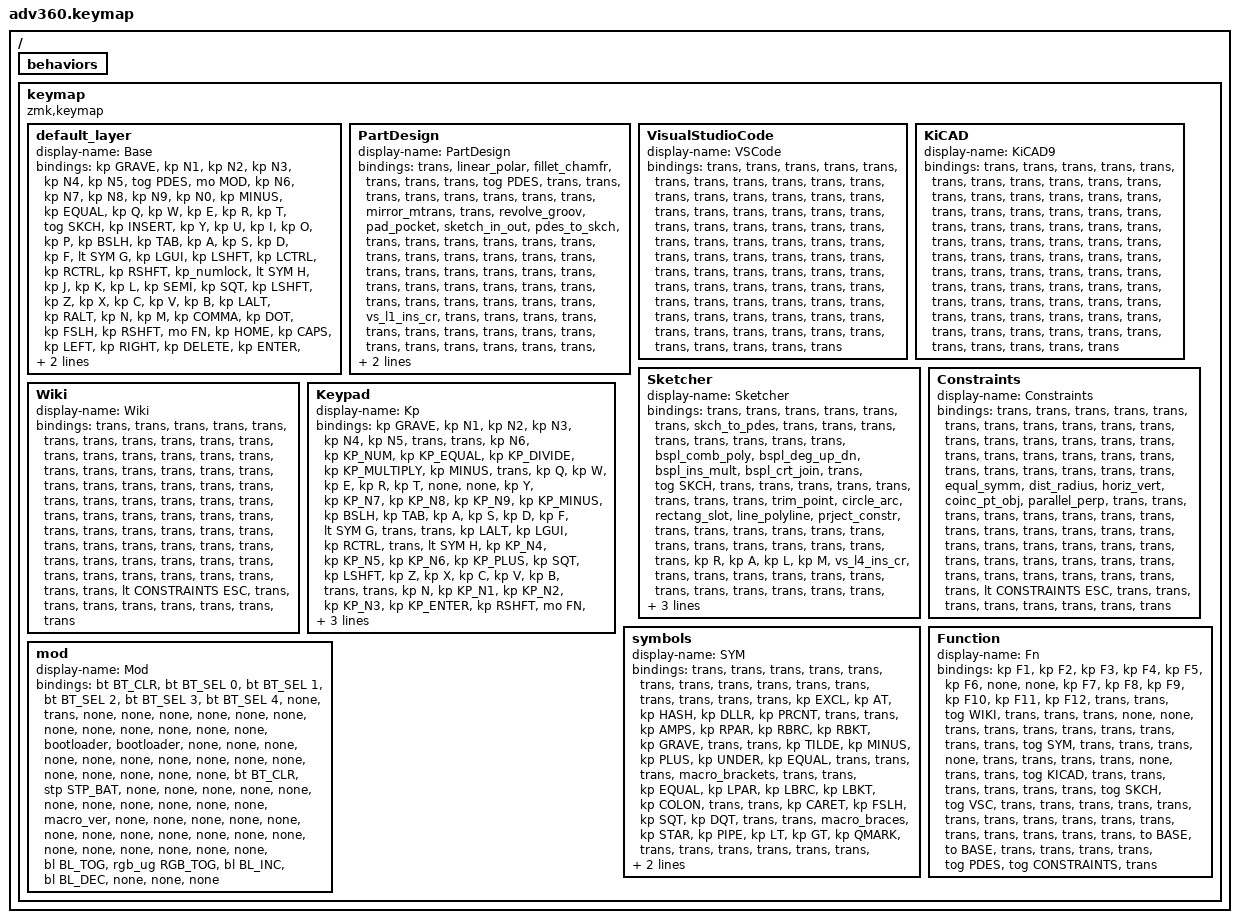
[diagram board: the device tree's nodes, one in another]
// ╔══════════════════════════════════════════════════════════════════════════╗
// ║  VISUAL HELPER TABLES: Each layer has an ASCII art comment block         ║
// ║  above its bindings that mirrors the physical key layout.                ║
// ║                                                                          ║
// ║  RULE: When editing ANY layer's bindings, the corresponding ASCII        ║
// ║  table comment MUST be updated to reflect the change. NEVER strip        ║
// ║  these comments. They are the human-readable source of truth.            ║
// ╚══════════════════════════════════════════════════════════════════════════╝

#include <behaviors.dtsi>
#include <dt-bindings/zmk/keys.h>
#include <dt-bindings/zmk/bt.h>
#include <dt-bindings/zmk/rgb.h>
#include <dt-bindings/zmk/stp.h>
#include <dt-bindings/zmk/backlight.h>
#include <dt-bindings/zmk/pointing.h>

#define BASE 0
#define PDES 1
#define VSC 2
#define KICAD 3
#define SKCH 4
#define CONSTRAINTS 5
#define WIKI 6
#define KP 7
#define SYM 8
#define FN 9
#define MOD 10

/ {
    behaviors {
      #include "version.dtsi"
      #include "macros.dtsi"
      #include "freecad.dtsi"
    };

  keymap {
    compatible = "zmk,keymap";

    default_layer {
      display-name = "Base";
      // ╔══════════════╦══════════════╦══════════════╦══════════════╦══════════════╦══════════════╦══════════════╗                                                                          ╔══════════════╦══════════════╦══════════════╦══════════════╦══════════════╦══════════════╦══════════════╗
      // ║  &kp GRAVE   ║    &kp N1    ║    &kp N2    ║    &kp N3    ║    &kp N4    ║    &kp N5    ║  &tog PDES   ║                                                                          ║   &mo MOD    ║    &kp N6    ║    &kp N7    ║    &kp N8    ║    &kp N9    ║    &kp N0    ║  &kp MINUS   ║
      // ╠══════════════╬══════════════╬══════════════╬══════════════╬══════════════╬══════════════╬══════════════╣                                                                          ╠══════════════╬══════════════╬══════════════╬══════════════╬══════════════╬══════════════╬══════════════╣
      // ║  &kp EQUAL   ║    &kp Q     ║    &kp W     ║    &kp E     ║    &kp R     ║    &kp T     ║  &tog SKCH   ║                                                                          ║  &kp INSERT  ║    &kp Y     ║    &kp U     ║    &kp I     ║    &kp O     ║    &kp P     ║   &kp BSLH   ║
      // ╠══════════════╬══════════════╬══════════════╬══════════════╬══════════════╬══════════════╬══════════════╣   ╔══════════════╦══════════════╗╔═══════════════╦══════════════╗        ╠══════════════╬══════════════╬══════════════╬══════════════╬══════════════╬══════════════╬══════════════╣
      // ║   &kp TAB    ║    &kp A     ║    &kp S     ║    &kp D     ║    &kp F     ║  &lt SYM G   ║   &kp LGUI   ║   ║  &kp LSHFT   ║  &kp LCTRL   ║║   &kp RCTRL   ║  &kp RSHFT   ║        ║ &kp_numlock  ║  &lt SYM H   ║    &kp J     ║    &kp K     ║    &kp L     ║   &kp SEMI   ║   &kp SQT    ║
      // ║              ║              ║              ║              ║              ║              ║              ║   ║              ║              ║║               ║              ║        ║              ║              ║              ║              ║              ║              ║              ║
      // ╠══════════════╬══════════════╬══════════════╬══════════════╬══════════════╬══════════════╬══════════════╝   ╚══════════════╬══════════════╣╠═══════════════╬══════════════╝        ╚══════════════╬══════════════╬══════════════╬══════════════╬══════════════╬══════════════╬══════════════╣
      // ║  &kp LSHFT   ║    &kp Z     ║    &kp X     ║    &kp C     ║    &kp V     ║    &kp B     ║                                 ║   &kp LALT   ║║   &kp RALT    ║                                      ║    &kp N     ║    &kp M     ║  &kp COMMA   ║   &kp DOT    ║   &kp FSLH   ║  &kp RSHFT   ║
      // ╠══════════════╬══════════════╬══════════════╬══════════════╬══════════════╬══════════════╝ ╔════════════════╦══════════════╬══════════════╣╠═══════════════╬══════════════╦═══════════╗           ╚══════════════╬══════════════╬══════════════╬══════════════╬══════════════╬══════════════╣
      // ║    &mo FN    ║   &kp HOME   ║   &kp CAPS   ║   &kp LEFT   ║  &kp RIGHT   ║                ║   &kp DELETE   ║  &kp ENTER   ║   &kp ESC    ║║    &kp ESC    ║  &kp SPACE   ║ &kp BSPC  ║                          ║    &kp UP    ║   &kp DOWN   ║   &kp LBKT   ║   &kp RBKT   ║    &mo FN    ║
      // ╚══════════════╩══════════════╩══════════════╩══════════════╩══════════════╝                ╚════════════════╩══════════════╩══════════════╝╚═══════════════╩══════════════╩═══════════╝                          ╚══════════════╩══════════════╩══════════════╩══════════════╩══════════════╝
            bindings = <
        &kp GRAVE &kp N1    &kp N2   &kp N3   &kp N4     &kp N5 &tog PDES                                                      &mo MOD    &kp N6 &kp N7 &kp N8    &kp N9   &kp N0   &kp MINUS
        &kp EQUAL &kp Q     &kp W    &kp E    &kp R      &kp T  &tog SKCH                                                      &kp INSERT &kp Y  &kp U  &kp I     &kp O    &kp P    &kp BSLH
        &kp TAB   &kp A     &kp S    &kp D    &kp F  &lt SYM G  &kp LGUI        &kp LSHFT    &kp LCTRL  &kp RCTRL &kp RSHFT   &kp_numlock &lt SYM H &kp J  &kp K     &kp L    &kp SEMI &kp SQT
        &kp LSHFT &kp Z     &kp X    &kp C    &kp V      &kp B                               &kp LALT  &kp RALT                        &kp N  &kp M  &kp COMMA &kp DOT  &kp FSLH &kp RSHFT
        &mo FN    &kp HOME  &kp CAPS &kp LEFT &kp RIGHT                &kp DELETE  &kp ENTER &kp ESC    &kp ESC   &kp SPACE  &kp BSPC         &kp UP &kp DOWN  &kp LBKT &kp RBKT &mo FN
      >;
    };

    PartDesign {
      display-name = "PartDesign";
      // ╔══════════════╦══════════════╦══════════════╦══════════════╦══════════════╦══════════════╦══════════════╗                                                                          ╔══════════════╦══════════════╦══════════════╦══════════════╦══════════════╦══════════════╦══════════════╗
      // ║    &trans    ║&linear_polar ║&fillet_chamfr║    &trans    ║    &trans    ║    &trans    ║  &tog PDES   ║                                                                          ║    &trans    ║    &trans    ║    &trans    ║    &trans    ║    &trans    ║  &vs_l1_ins_cr  ║    &trans    ║
      // ╠══════════════╬══════════════╬══════════════╬══════════════╬══════════════╬══════════════╬══════════════╣                                                                          ╠══════════════╬══════════════╬══════════════╬══════════════╬══════════════╬══════════════╬══════════════╣
      // ║    &trans    ║&mirror_mtrans║    &trans    ║&revolve_groov║ &pad_pocket  ║&sketch_in_out║&pdes_to_skch ║                                                                          ║    &trans    ║    &trans    ║    &trans    ║    &trans    ║    &trans    ║    &trans    ║    &trans    ║
      // ╠══════════════╬══════════════╬══════════════╬══════════════╬══════════════╬══════════════╬══════════════╣   ╔══════════════╦══════════════╗╔═══════════════╦══════════════╗        ╠══════════════╬══════════════╬══════════════╬══════════════╬══════════════╬══════════════╬══════════════╣
      // ║    &trans    ║    &trans    ║    &trans    ║    &trans    ║    &trans    ║    &trans    ║    &trans    ║   ║    &trans    ║    &trans    ║║    &trans     ║    &trans    ║        ║    &trans    ║    &trans    ║    &trans    ║    &trans    ║    &trans    ║    &trans    ║    &trans    ║
      // ║              ║              ║              ║              ║              ║              ║              ║   ║              ║              ║║               ║              ║        ║              ║              ║              ║              ║              ║              ║              ║
      // ╠══════════════╬══════════════╬══════════════╬══════════════╬══════════════╬══════════════╬══════════════╝   ╚══════════════╬══════════════╣╠═══════════════╬══════════════╝        ╚══════════════╬══════════════╬══════════════╬══════════════╬══════════════╬══════════════╬══════════════╣
      // ║    &trans    ║    &trans    ║    &trans    ║    &trans    ║    &trans    ║    &trans    ║                                 ║    &trans    ║║    &trans     ║                                      ║    &trans    ║    &trans    ║    &trans    ║    &trans    ║    &trans    ║    &trans    ║
      // ╠══════════════╬══════════════╬══════════════╬══════════════╬══════════════╬══════════════╝ ╔════════════════╦══════════════╬══════════════╣╠═══════════════╬══════════════╦═══════════╗           ╚══════════════╬══════════════╬══════════════╬══════════════╬══════════════╬══════════════╣
      // ║    &trans    ║    &trans    ║    &trans    ║    &trans    ║    &trans    ║                ║     &trans     ║    &trans    ║    &trans    ║║    &trans     ║    &trans    ║  &trans   ║                          ║    &trans    ║    &trans    ║    &trans    ║    &trans    ║    &trans    ║
      // ╚══════════════╩══════════════╩══════════════╩══════════════╩══════════════╝                ╚════════════════╩══════════════╩══════════════╝╚═══════════════╩══════════════╩═══════════╝                          ╚══════════════╩══════════════╩══════════════╩══════════════╩══════════════╝
            bindings = <
        &trans &linear_polar &fillet_chamfr &trans &trans &trans &tog PDES                                                    &trans &trans &trans &trans &trans &trans &trans
        &trans &mirror_mtrans &trans &revolve_groov &pad_pocket &sketch_in_out &pdes_to_skch                                  &trans &trans &trans &trans &trans &trans &trans
        &trans &trans &trans &trans &trans &trans &trans       &trans &trans    &trans &trans &trans &trans &trans &trans &trans &trans &trans
        &trans &trans &trans &trans &trans &vs_l1_ins_cr                 &trans &trans                     &trans &trans &trans &trans &trans &trans
        &trans &trans &trans &trans &trans        &trans &trans &trans       &trans &trans &trans        &trans &trans &trans &trans &trans
      >;
    };

    VisualStudioCode {
      display-name = "VSCode";
      // ╔══════════════╦══════════════╦══════════════╦══════════════╦══════════════╦══════════════╦══════════════╗                                                                          ╔══════════════╦══════════════╦══════════════╦══════════════╦══════════════╦══════════════╦══════════════╗
      // ║    &trans    ║    &trans    ║    &trans    ║    &trans    ║    &trans    ║    &trans    ║    &trans    ║                                                                          ║    &trans    ║    &trans    ║    &trans    ║    &trans    ║    &trans    ║    &trans    ║    &trans    ║
      // ╠══════════════╬══════════════╬══════════════╬══════════════╬══════════════╬══════════════╬══════════════╣                                                                          ╠══════════════╬══════════════╬══════════════╬══════════════╬══════════════╬══════════════╬══════════════╣
      // ║    &trans    ║    &trans    ║    &trans    ║    &trans    ║    &trans    ║    &trans    ║    &trans    ║                                                                          ║    &trans    ║    &trans    ║    &trans    ║    &trans    ║    &trans    ║    &trans    ║    &trans    ║
      // ╠══════════════╬══════════════╬══════════════╬══════════════╬══════════════╬══════════════╬══════════════╣   ╔══════════════╦══════════════╗╔═══════════════╦══════════════╗        ╠══════════════╬══════════════╬══════════════╬══════════════╬══════════════╬══════════════╬══════════════╣
      // ║    &trans    ║    &trans    ║    &trans    ║    &trans    ║    &trans    ║    &trans    ║    &trans    ║   ║    &trans    ║    &trans    ║║    &trans     ║    &trans    ║        ║    &trans    ║    &trans    ║    &trans    ║    &trans    ║    &trans    ║    &trans    ║    &trans    ║
      // ║              ║              ║              ║              ║              ║              ║              ║   ║              ║              ║║               ║              ║        ║              ║              ║              ║              ║              ║              ║              ║
      // ╠══════════════╬══════════════╬══════════════╬══════════════╬══════════════╬══════════════╬══════════════╝   ╚══════════════╬══════════════╣╠═══════════════╬══════════════╝        ╚══════════════╬══════════════╬══════════════╬══════════════╬══════════════╬══════════════╬══════════════╣
      // ║    &trans    ║    &trans    ║    &trans    ║    &trans    ║    &trans    ║    &trans    ║                                 ║    &trans    ║║    &trans     ║                                      ║    &trans    ║    &trans    ║    &trans    ║    &trans    ║    &trans    ║    &trans    ║
      // ╠══════════════╬══════════════╬══════════════╬══════════════╬══════════════╬══════════════╝ ╔════════════════╦══════════════╬══════════════╣╠═══════════════╬══════════════╦═══════════╗           ╚══════════════╬══════════════╬══════════════╬══════════════╬══════════════╬══════════════╣
      // ║    &trans    ║    &trans    ║    &trans    ║    &trans    ║    &trans    ║                ║     &trans     ║    &trans    ║    &trans    ║║    &trans     ║    &trans    ║  &trans   ║                          ║    &trans    ║    &trans    ║    &trans    ║    &trans    ║    &trans    ║
      // ╚══════════════╩══════════════╩══════════════╩══════════════╩══════════════╝                ╚════════════════╩══════════════╩══════════════╝╚═══════════════╩══════════════╩═══════════╝                          ╚══════════════╩══════════════╩══════════════╩══════════════╩══════════════╝
            bindings = <
        &trans &trans &trans &trans &trans &trans &trans                                          &trans &trans &trans &trans &trans &trans &trans
        &trans &trans &trans &trans &trans &trans &trans                                           &trans &trans &trans &trans &trans &trans &trans
        &trans &trans &trans &trans &trans &trans &trans &trans &trans       &trans &trans &trans &trans &trans &trans &trans &trans &trans
        &trans &trans &trans &trans &trans &trans                      &trans &trans                     &trans &trans &trans &trans &trans &trans
        &trans &trans &trans &trans &trans        &trans &trans &trans       &trans &trans &trans        &trans &trans &trans &trans &trans
      >;
    };

    KiCAD {
      display-name = "KiCAD9";
      // ╔══════════════╦══════════════╦══════════════╦══════════════╦══════════════╦══════════════╦══════════════╗                                                                          ╔══════════════╦══════════════╦══════════════╦══════════════╦══════════════╦══════════════╦══════════════╗
      // ║    &trans    ║    &trans    ║    &trans    ║    &trans    ║    &trans    ║    &trans    ║    &trans    ║                                                                          ║    &trans    ║    &trans    ║    &trans    ║    &trans    ║    &trans    ║    &trans    ║    &trans    ║
      // ╠══════════════╬══════════════╬══════════════╬══════════════╬══════════════╬══════════════╬══════════════╣                                                                          ╠══════════════╬══════════════╬══════════════╬══════════════╬══════════════╬══════════════╬══════════════╣
      // ║    &trans    ║    &trans    ║    &trans    ║    &trans    ║    &trans    ║    &trans    ║    &trans    ║                                                                          ║    &trans    ║    &trans    ║    &trans    ║    &trans    ║    &trans    ║    &trans    ║    &trans    ║
      // ╠══════════════╬══════════════╬══════════════╬══════════════╬══════════════╬══════════════╬══════════════╣   ╔══════════════╦══════════════╗╔═══════════════╦══════════════╗        ╠══════════════╬══════════════╬══════════════╬══════════════╬══════════════╬══════════════╬══════════════╣
      // ║    &trans    ║    &trans    ║    &trans    ║    &trans    ║    &trans    ║    &trans    ║    &trans    ║   ║    &trans    ║    &trans    ║║    &trans     ║    &trans    ║        ║    &trans    ║    &trans    ║    &trans    ║    &trans    ║    &trans    ║    &trans    ║    &trans    ║
      // ║              ║              ║              ║              ║              ║              ║              ║   ║              ║              ║║               ║              ║        ║              ║              ║              ║              ║              ║              ║              ║
      // ╠══════════════╬══════════════╬══════════════╬══════════════╬══════════════╬══════════════╬══════════════╝   ╚══════════════╬══════════════╣╠═══════════════╬══════════════╝        ╚══════════════╬══════════════╬══════════════╬══════════════╬══════════════╬══════════════╬══════════════╣
      // ║    &trans    ║    &trans    ║    &trans    ║    &trans    ║    &trans    ║    &trans    ║                                 ║    &trans    ║║    &trans     ║                                      ║    &trans    ║    &trans    ║    &trans    ║    &trans    ║    &trans    ║    &trans    ║
      // ╠══════════════╬══════════════╬══════════════╬══════════════╬══════════════╬══════════════╝ ╔════════════════╦══════════════╬══════════════╣╠═══════════════╬══════════════╦═══════════╗           ╚══════════════╬══════════════╬══════════════╬══════════════╬══════════════╬══════════════╣
      // ║    &trans    ║    &trans    ║    &trans    ║    &trans    ║    &trans    ║                ║     &trans     ║    &trans    ║    &trans    ║║    &trans     ║    &trans    ║  &trans   ║                          ║    &trans    ║    &trans    ║    &trans    ║    &trans    ║    &trans    ║
      // ╚══════════════╩══════════════╩══════════════╩══════════════╩══════════════╝                ╚════════════════╩══════════════╩══════════════╝╚═══════════════╩══════════════╩═══════════╝                          ╚══════════════╩══════════════╩══════════════╩══════════════╩══════════════╝
            bindings = <
        &trans &trans &trans &trans &trans &trans &trans                                          &trans &trans &trans &trans &trans &trans &trans
        &trans &trans &trans &trans &trans &trans &trans                                           &trans &trans &trans &trans &trans &trans &trans
        &trans &trans &trans &trans &trans &trans &trans &trans &trans       &trans &trans &trans &trans &trans &trans &trans &trans &trans
        &trans &trans &trans &trans &trans &trans                      &trans &trans                     &trans &trans &trans &trans &trans &trans
        &trans &trans &trans &trans &trans        &trans &trans &trans       &trans &trans &trans        &trans &trans &trans &trans &trans
      >;
    };

    Sketcher {
      display-name = "Sketcher";
      // ╔══════════════╦══════════════╦══════════════╦══════════════╦══════════════╦══════════════╦══════════════╗                                                                          ╔══════════════╦══════════════╦══════════════╦══════════════╦══════════════╦══════════════╦══════════════╗
      // ║    &trans    ║    &trans    ║    &trans    ║    &trans    ║    &trans    ║    &trans    ║&skch_to_pdes ║                                                                          ║    &trans    ║    &trans    ║    &trans    ║    &trans    ║    &trans    ║    &trans    ║    &trans    ║
      // ╠══════════════╬══════════════╬══════════════╬══════════════╬══════════════╬══════════════╬══════════════╣                                                                          ╠══════════════╬══════════════╬══════════════╬══════════════╬══════════════╬══════════════╬══════════════╣
      // ║    &trans    ║&bspl_comb_pol║&bspl_deg_up_d║&bspl_ins_mult║&bspl_crt_join║    &trans    ║  &tog SKCH   ║                                                                          ║    &trans    ║    &trans    ║    &trans    ║    &trans    ║    &trans    ║    &trans    ║    &trans    ║
      // ╠══════════════╬══════════════╬══════════════╬══════════════╬══════════════╬══════════════╬══════════════╣   ╔══════════════╦══════════════╗╔═══════════════╦══════════════╗        ╠══════════════╬══════════════╬══════════════╬══════════════╬══════════════╬══════════════╬══════════════╣
      // ║    &trans    ║ &trim_point  ║ &circle_arc  ║&rectang_slot ║&line_polyline║&prject_constr║    &trans    ║   ║    &trans    ║    &trans    ║║    &trans     ║    &trans    ║        ║    &trans    ║    &trans    ║    &trans    ║    &trans    ║    &trans    ║    &trans    ║    &trans    ║
      // ║              ║              ║              ║              ║              ║              ║              ║   ║              ║              ║║               ║              ║        ║              ║              ║              ║              ║              ║              ║              ║
      // ╠══════════════╬══════════════╬══════════════╬══════════════╬══════════════╬══════════════╬══════════════╝   ╚══════════════╬══════════════╣╠═══════════════╬══════════════╝        ╚══════════════╬══════════════╬══════════════╬══════════════╬══════════════╬══════════════╬══════════════╣
      // ║    &trans    ║    &kp R     ║    &kp A     ║    &kp L     ║    &kp M     ║  &vs_l4_ins_cr  ║                                 ║    &trans    ║║    &trans     ║                                      ║    &trans    ║    &trans    ║    &trans    ║    &trans    ║    &trans    ║    &trans    ║
      // ╠══════════════╬══════════════╬══════════════╬══════════════╬══════════════╬══════════════╝ ╔════════════════╦══════════════╬══════════════╣╠═══════════════╬══════════════╦═══════════╗           ╚══════════════╬══════════════╬══════════════╬══════════════╬══════════════╬══════════════╣
      // ║    &trans    ║    &trans    ║    &trans    ║    &trans    ║    &trans    ║                ║     &trans     ║    &trans    ║&lt CONSTRAINT║║    &trans     ║    &trans    ║  &trans   ║                          ║    &trans    ║    &trans    ║    &trans    ║    &trans    ║    &trans    ║
      // ╚══════════════╩══════════════╩══════════════╩══════════════╩══════════════╝                ╚════════════════╩══════════════╩══════════════╝╚═══════════════╩══════════════╩═══════════╝                          ╚══════════════╩══════════════╩══════════════╩══════════════╩══════════════╝
            bindings = <
        &trans &trans &trans &trans &trans &trans &skch_to_pdes                                                    &trans &trans &trans &trans &trans &trans &trans
        &trans &bspl_comb_poly &bspl_deg_up_dn &bspl_ins_mult &bspl_crt_join &trans &tog SKCH                                                        &trans &trans &trans &trans &trans &trans &trans
        &trans &trim_point &circle_arc &rectang_slot &line_polyline &prject_constr &trans       &trans &trans    &trans &trans &trans &trans &trans &trans &trans &trans &trans
        &trans &kp R  &kp A  &kp L  &kp M &vs_l4_ins_cr                 &trans &trans                     &trans &trans &trans &trans &trans &trans
        &trans &trans &trans &trans &trans                             &trans &trans &lt CONSTRAINTS ESC  &trans &trans &trans                        &trans &trans &trans &trans &trans
      >;
    };

    Constraints {
      display-name = "Constraints";
      // ╔══════════════╦══════════════╦══════════════╦══════════════╦══════════════╦══════════════╦══════════════╗                                                                          ╔══════════════╦══════════════╦══════════════╦══════════════╦══════════════╦══════════════╦══════════════╗
      // ║    &trans    ║    &trans    ║    &trans    ║    &trans    ║    &trans    ║    &trans    ║    &trans    ║                                                                          ║    &trans    ║    &trans    ║    &trans    ║    &trans    ║    &trans    ║    &trans    ║    &trans    ║
      // ╠══════════════╬══════════════╬══════════════╬══════════════╬══════════════╬══════════════╬══════════════╣                                                                          ╠══════════════╬══════════════╬══════════════╬══════════════╬══════════════╬══════════════╬══════════════╣
      // ║    &trans    ║    &trans    ║    &trans    ║    &trans    ║    &trans    ║    &trans    ║    &trans    ║                                                                          ║    &trans    ║    &trans    ║    &trans    ║    &trans    ║    &trans    ║    &trans    ║    &trans    ║
      // ╠══════════════╬══════════════╬══════════════╬══════════════╬══════════════╬══════════════╬══════════════╣   ╔══════════════╦══════════════╗╔═══════════════╦══════════════╗        ╠══════════════╬══════════════╬══════════════╬══════════════╬══════════════╬══════════════╬══════════════╣
      // ║    &trans    ║ &equal_symm  ║ &dist_radius ║ &horiz_vert  ║&coinc_pt_obj ║&parallel_perp║    &trans    ║   ║    &trans    ║    &trans    ║║    &trans     ║    &trans    ║        ║    &trans    ║    &trans    ║    &trans    ║    &trans    ║    &trans    ║    &trans    ║    &trans    ║
      // ║              ║              ║              ║              ║              ║              ║              ║   ║              ║              ║║               ║              ║        ║              ║              ║              ║              ║              ║              ║              ║
      // ╠══════════════╬══════════════╬══════════════╬══════════════╬══════════════╬══════════════╬══════════════╝   ╚══════════════╬══════════════╣╠═══════════════╬══════════════╝        ╚══════════════╬══════════════╬══════════════╬══════════════╬══════════════╬══════════════╬══════════════╣
      // ║    &trans    ║    &trans    ║    &trans    ║    &trans    ║    &trans    ║    &trans    ║                                 ║    &trans    ║║    &trans     ║                                      ║    &trans    ║    &trans    ║    &trans    ║    &trans    ║    &trans    ║    &trans    ║
      // ╠══════════════╬══════════════╬══════════════╬══════════════╬══════════════╬══════════════╝ ╔════════════════╦══════════════╬══════════════╣╠═══════════════╬══════════════╦═══════════╗           ╚══════════════╬══════════════╬══════════════╬══════════════╬══════════════╬══════════════╣
      // ║    &trans    ║    &trans    ║    &trans    ║    &trans    ║    &trans    ║                ║     &trans     ║    &trans    ║&lt CONSTRAINT║║    &trans     ║    &trans    ║  &trans   ║                          ║    &trans    ║    &trans    ║    &trans    ║    &trans    ║    &trans    ║
      // ╚══════════════╩══════════════╩══════════════╩══════════════╩══════════════╝                ╚════════════════╩══════════════╩══════════════╝╚═══════════════╩══════════════╩═══════════╝                          ╚══════════════╩══════════════╩══════════════╩══════════════╩══════════════╝
            bindings = <
        &trans &trans &trans &trans &trans &trans &trans                                                                       &trans &trans &trans &trans &trans &trans &trans
        &trans &trans &trans &trans &trans &trans &trans                                                                       &trans &trans &trans &trans &trans &trans &trans
        &trans &equal_symm &dist_radius &horiz_vert &coinc_pt_obj &parallel_perp &trans    &trans &trans   &trans &trans   &trans &trans &trans &trans &trans &trans &trans
        &trans &trans &trans &trans &trans &trans                                              &trans &trans                   &trans &trans &trans &trans &trans &trans
        &trans &trans &trans &trans &trans                             &trans &trans &lt CONSTRAINTS ESC    &trans &trans &trans                   &trans &trans &trans &trans &trans
      >;
    };

    Wiki {
      display-name = "Wiki";
      // ╔══════════════╦══════════════╦══════════════╦══════════════╦══════════════╦══════════════╦══════════════╗                                                                          ╔══════════════╦══════════════╦══════════════╦══════════════╦══════════════╦══════════════╦══════════════╗
      // ║    &trans    ║    &trans    ║    &trans    ║    &trans    ║    &trans    ║    &trans    ║    &trans    ║                                                                          ║    &trans    ║    &trans    ║    &trans    ║    &trans    ║    &trans    ║    &trans    ║    &trans    ║
      // ╠══════════════╬══════════════╬══════════════╬══════════════╬══════════════╬══════════════╬══════════════╣                                                                          ╠══════════════╬══════════════╬══════════════╬══════════════╬══════════════╬══════════════╬══════════════╣
      // ║    &trans    ║    &trans    ║    &trans    ║    &trans    ║    &trans    ║    &trans    ║    &trans    ║                                                                          ║    &trans    ║    &trans    ║    &trans    ║    &trans    ║    &trans    ║    &trans    ║    &trans    ║
      // ╠══════════════╬══════════════╬══════════════╬══════════════╬══════════════╬══════════════╬══════════════╣   ╔══════════════╦══════════════╗╔═══════════════╦══════════════╗        ╠══════════════╬══════════════╬══════════════╬══════════════╬══════════════╬══════════════╬══════════════╣
      // ║    &trans    ║    &trans    ║    &trans    ║    &trans    ║    &trans    ║    &trans    ║    &trans    ║   ║    &trans    ║    &trans    ║║    &trans     ║    &trans    ║        ║    &trans    ║    &trans    ║    &trans    ║    &trans    ║    &trans    ║    &trans    ║    &trans    ║
      // ║              ║              ║              ║              ║              ║              ║              ║   ║              ║              ║║               ║              ║        ║              ║              ║              ║              ║              ║              ║              ║
      // ╠══════════════╬══════════════╬══════════════╬══════════════╬══════════════╬══════════════╬══════════════╝   ╚══════════════╬══════════════╣╠═══════════════╬══════════════╝        ╚══════════════╬══════════════╬══════════════╬══════════════╬══════════════╬══════════════╬══════════════╣
      // ║    &trans    ║    &trans    ║    &trans    ║    &trans    ║    &trans    ║    &trans    ║                                 ║    &trans    ║║    &trans     ║                                      ║    &trans    ║    &trans    ║    &trans    ║    &trans    ║    &trans    ║    &trans    ║
      // ╠══════════════╬══════════════╬══════════════╬══════════════╬══════════════╬══════════════╝ ╔════════════════╦══════════════╬══════════════╣╠═══════════════╬══════════════╦═══════════╗           ╚══════════════╬══════════════╬══════════════╬══════════════╬══════════════╬══════════════╣
      // ║    &trans    ║    &trans    ║    &trans    ║    &trans    ║    &trans    ║                ║     &trans     ║    &trans    ║&lt CONSTRAINT║║    &trans     ║    &trans    ║  &trans   ║                          ║    &trans    ║    &trans    ║    &trans    ║    &trans    ║    &trans    ║
      // ╚══════════════╩══════════════╩══════════════╩══════════════╩══════════════╝                ╚════════════════╩══════════════╩══════════════╝╚═══════════════╩══════════════╩═══════════╝                          ╚══════════════╩══════════════╩══════════════╩══════════════╩══════════════╝
            bindings = <
        &trans &trans &trans &trans &trans &trans &trans                                          &trans &trans &trans &trans &trans &trans &trans
        &trans &trans &trans &trans &trans &trans &trans                                           &trans &trans &trans &trans &trans &trans &trans
        &trans &trans &trans &trans &trans &trans &trans &trans &trans       &trans &trans &trans &trans &trans &trans &trans &trans &trans
        &trans &trans &trans &trans &trans &trans                      &trans &trans                     &trans &trans &trans &trans &trans &trans
        &trans &trans &trans &trans &trans        &trans &trans &lt CONSTRAINTS ESC       &trans &trans &trans        &trans &trans &trans &trans &trans
      >;
    };

Keypad {
      display-name = "Kp";
      // ╔══════════════╦══════════════╦══════════════╦══════════════╦══════════════╦══════════════╦══════════════╗                                                                          ╔══════════════╦══════════════╦══════════════╦══════════════╦══════════════╦══════════════╦══════════════╗
      // ║  &kp GRAVE   ║    &kp N1    ║    &kp N2    ║    &kp N3    ║    &kp N4    ║    &kp N5    ║    &trans    ║                                                                          ║    &trans    ║    &kp N6    ║  &kp KP_NUM  ║ &kp KP_EQUAL ║&kp KP_DIVIDE ║&kp KP_MULTIPL║  &kp MINUS   ║
      // ╠══════════════╬══════════════╬══════════════╬══════════════╬══════════════╬══════════════╬══════════════╣                                                                          ╠══════════════╬══════════════╬══════════════╬══════════════╬══════════════╬══════════════╬══════════════╣
      // ║    &trans    ║    &kp Q     ║    &kp W     ║    &kp E     ║    &kp R     ║    &kp T     ║    &none     ║                                                                          ║    &none     ║    &kp Y     ║  &kp KP_N7   ║  &kp KP_N8   ║  &kp KP_N9   ║ &kp KP_MINUS ║   &kp BSLH   ║
      // ╠══════════════╬══════════════╬══════════════╬══════════════╬══════════════╬══════════════╬══════════════╣   ╔══════════════╦══════════════╗╔═══════════════╦══════════════╗        ╠══════════════╬══════════════╬══════════════╬══════════════╬══════════════╬══════════════╬══════════════╣
      // ║   &kp TAB    ║    &kp A     ║    &kp S     ║    &kp D     ║    &kp F     ║  &lt SYM G   ║    &trans    ║   ║    &trans    ║   &kp LALT   ║║   &kp LGUI    ║  &kp RCTRL   ║        ║    &trans    ║  &lt SYM H   ║  &kp KP_N4   ║  &kp KP_N5   ║  &kp KP_N6   ║ &kp KP_PLUS  ║   &kp SQT    ║
      // ║              ║              ║              ║              ║              ║              ║              ║   ║              ║              ║║               ║              ║        ║              ║              ║              ║              ║              ║              ║              ║
      // ╠══════════════╬══════════════╬══════════════╬══════════════╬══════════════╬══════════════╬══════════════╝   ╚══════════════╬══════════════╣╠═══════════════╬══════════════╝        ╚══════════════╬══════════════╬══════════════╬══════════════╬══════════════╬══════════════╬══════════════╣
      // ║  &kp LSHFT   ║    &kp Z     ║    &kp X     ║    &kp C     ║    &kp V     ║    &kp B     ║                                 ║    &trans    ║║    &trans     ║                                      ║    &kp N     ║  &kp KP_N1   ║  &kp KP_N2   ║  &kp KP_N3   ║ &kp KP_ENTER ║  &kp RSHFT   ║
      // ╠══════════════╬══════════════╬══════════════╬══════════════╬══════════════╬══════════════╝ ╔════════════════╦══════════════╬══════════════╣╠═══════════════╬══════════════╦═══════════╗           ╚══════════════╬══════════════╬══════════════╬══════════════╬══════════════╬══════════════╣
      // ║    &mo FN    ║    &trans    ║   &kp CAPS   ║   &kp LEFT   ║  &kp RIGHT   ║                ║     &trans     ║    &trans    ║    &trans    ║║    &trans     ║  &kp KP_N0   ║  &trans   ║                          ║    &kp UP    ║   &kp DOWN   ║  &kp KP_DOT  ║   &kp RBKT   ║   &tog SYM   ║
      // ╚══════════════╩══════════════╩══════════════╩══════════════╩══════════════╝                ╚════════════════╩══════════════╩══════════════╝╚═══════════════╩══════════════╩═══════════╝                          ╚══════════════╩══════════════╩══════════════╩══════════════╩══════════════╝
            bindings = <
        &kp GRAVE &kp N1    &kp N2   &kp N3   &kp N4     &kp N5 &trans                                                           &trans &kp N6 &kp KP_NUM &kp KP_EQUAL &kp KP_DIVIDE &kp KP_MULTIPLY &kp MINUS
        &trans    &kp Q     &kp W    &kp E    &kp R      &kp T  &none                                                            &none &kp Y  &kp KP_N7  &kp KP_N8    &kp KP_N9     &kp KP_MINUS    &kp BSLH
        &kp TAB   &kp A     &kp S    &kp D    &kp F      &lt SYM G  &trans        &trans  &kp LALT     &kp LGUI  &kp RCTRL           &trans &lt SYM H  &kp KP_N4  &kp KP_N5    &kp KP_N6     &kp KP_PLUS     &kp SQT
        &kp LSHFT &kp Z     &kp X    &kp C    &kp V      &kp B                       &trans        &trans                               &kp N  &kp KP_N1  &kp KP_N2    &kp KP_N3     &kp KP_ENTER    &kp RSHFT
        &mo FN    &trans    &kp CAPS &kp LEFT &kp RIGHT                &trans &trans &trans &trans &kp KP_N0 &trans                            &kp UP     &kp DOWN     &kp KP_DOT    &kp RBKT        &tog SYM
      >;
    };

    symbols {
      display-name = "SYM";
      // ╔══════════════╦══════════════╦══════════════╦══════════════╦══════════════╦══════════════╦══════════════╗                                                                          ╔══════════════╦══════════════╦══════════════╦══════════════╦══════════════╦══════════════╦══════════════╗
      // ║    &trans    ║    &trans    ║    &trans    ║    &trans    ║    &trans    ║    &trans    ║    &trans    ║                                                                          ║    &trans    ║    &trans    ║    &trans    ║    &trans    ║    &trans    ║    &trans    ║    &trans    ║
      // ╠══════════════╬══════════════╬══════════════╬══════════════╬══════════════╬══════════════╬══════════════╣                                                                          ╠══════════════╬══════════════╬══════════════╬══════════════╬══════════════╬══════════════╬══════════════╣
      // ║    &trans    ║   &kp EXCL   ║    &kp AT    ║   &kp HASH   ║   &kp DLLR   ║  &kp PRCNT   ║    &trans    ║                                                                          ║    &trans    ║   &kp AMPS   ║   &kp RPAR   ║   &kp RBRC   ║   &kp RBKT   ║  &kp GRAVE   ║    &trans    ║
      // ╠══════════════╬══════════════╬══════════════╬══════════════╬══════════════╬══════════════╬══════════════╣   ╔══════════════╦══════════════╗╔═══════════════╦══════════════╗        ╠══════════════╬══════════════╬══════════════╬══════════════╬══════════════╬══════════════╬══════════════╣
      // ║    &trans    ║  &kp TILDE   ║  &kp MINUS   ║   &kp PLUS   ║  &kp UNDER   ║  &kp EQUAL   ║    &trans    ║   ║    &trans    ║    &trans    ║║&macro_brackets║    &trans    ║        ║    &trans    ║  &kp EQUAL   ║   &kp LPAR   ║   &kp LBRC   ║   &kp LBKT   ║  &kp COLON   ║    &trans    ║
      // ║              ║              ║              ║              ║              ║              ║              ║   ║              ║              ║║               ║              ║        ║              ║              ║              ║              ║              ║              ║              ║
      // ╠══════════════╬══════════════╬══════════════╬══════════════╬══════════════╬══════════════╬══════════════╝   ╚══════════════╬══════════════╣╠═══════════════╬══════════════╝        ╚══════════════╬══════════════╬══════════════╬══════════════╬══════════════╬══════════════╬══════════════╣
      // ║    &trans    ║  &kp CARET   ║   &kp FSLH   ║   &kp SQT    ║   &kp DQT    ║    &trans    ║                                 ║    &trans    ║║ &macro_braces ║                                      ║   &kp STAR   ║   &kp PIPE   ║    &kp LT    ║    &kp GT    ║  &kp QMARK   ║    &trans    ║
      // ╠══════════════╬══════════════╬══════════════╬══════════════╬══════════════╬══════════════╝ ╔════════════════╦══════════════╬══════════════╣╠═══════════════╬══════════════╦═══════════╗           ╚══════════════╬══════════════╬══════════════╬══════════════╬══════════════╬══════════════╣
      // ║    &trans    ║    &trans    ║    &trans    ║    &trans    ║    &trans    ║                ║     &trans     ║    &trans    ║    &trans    ║║ &macro_parens ║    &trans    ║  &trans   ║                          ║    &trans    ║    &trans    ║    &trans    ║    &trans    ║    &trans    ║
      // ╚══════════════╩══════════════╩══════════════╩══════════════╩══════════════╝                ╚════════════════╩══════════════╩══════════════╝╚═══════════════╩══════════════╩═══════════╝                          ╚══════════════╩══════════════╩══════════════╩══════════════╩══════════════╝
            bindings = <
        &trans &trans &trans &trans &trans &trans &trans                                           &trans &trans &trans &trans &trans &trans &trans
        &trans &kp EXCL &kp AT &kp HASH &kp DLLR &kp PRCNT &trans                                  &trans &kp AMPS &kp RPAR &kp RBRC &kp RBKT &kp GRAVE &trans
        &trans &kp TILDE &kp MINUS &kp PLUS &kp UNDER &kp EQUAL &trans &trans &trans  &macro_brackets &trans &trans &kp EQUAL &kp LPAR &kp LBRC &kp LBKT &kp COLON &trans
        &trans &kp CARET &kp FSLH &kp SQT &kp DQT &trans                 &trans &macro_braces                    &kp STAR &kp PIPE &kp LT &kp GT &kp QMARK &trans
        &trans &trans &trans &trans &trans             &trans &trans &trans       &macro_parens &trans &trans             &trans &trans &trans &trans &trans
      >;
    };

    Function {
      display-name = "Fn";
      // ╔══════════════╦══════════════╦══════════════╦══════════════╦══════════════╦══════════════╦══════════════╗                                                                          ╔══════════════╦══════════════╦══════════════╦══════════════╦══════════════╦══════════════╦══════════════╗
      // ║    &kp F1    ║    &kp F2    ║    &kp F3    ║    &kp F4    ║    &kp F5    ║    &kp F6    ║    &none     ║                                                                          ║    &none     ║    &kp F7    ║    &kp F8    ║    &kp F9    ║   &kp F10    ║   &kp F11    ║   &kp F12    ║
      // ╠══════════════╬══════════════╬══════════════╬══════════════╬══════════════╬══════════════╬══════════════╣                                                                          ╠══════════════╬══════════════╬══════════════╬══════════════╬══════════════╬══════════════╬══════════════╣
      // ║    &trans    ║    &trans    ║  &tog WIKI   ║    &trans    ║    &trans    ║    &trans    ║    &none     ║                                                                          ║    &none     ║    &trans    ║    &trans    ║    &trans    ║    &trans    ║    &trans    ║    &trans    ║
      // ╠══════════════╬══════════════╬══════════════╬══════════════╬══════════════╬══════════════╬══════════════╣   ╔══════════════╦══════════════╗╔═══════════════╦══════════════╗        ╠══════════════╬══════════════╬══════════════╬══════════════╬══════════════╬══════════════╬══════════════╣
      // ║    &trans    ║    &trans    ║   &tog SYM   ║    &trans    ║    &trans    ║    &trans    ║    &none     ║   ║    &trans    ║    &trans    ║║    &trans     ║    &trans    ║        ║    &none     ║    &trans    ║    &trans    ║  &tog KICAD  ║    &trans    ║    &trans    ║    &trans    ║
      // ║              ║              ║              ║              ║              ║              ║              ║   ║              ║              ║║               ║              ║        ║              ║              ║              ║              ║              ║              ║              ║
      // ╠══════════════╬══════════════╬══════════════╬══════════════╬══════════════╬══════════════╬══════════════╝   ╚══════════════╬══════════════╣╠═══════════════╬══════════════╝        ╚══════════════╬══════════════╬══════════════╬══════════════╬══════════════╬══════════════╬══════════════╣
      // ║    &trans    ║    &trans    ║    &trans    ║  &tog SKCH   ║   &tog VSC   ║    &trans    ║                                 ║    &trans    ║║    &trans     ║                                      ║    &trans    ║    &trans    ║    &trans    ║    &trans    ║    &trans    ║    &trans    ║
      // ╠══════════════╬══════════════╬══════════════╬══════════════╬══════════════╬══════════════╝ ╔════════════════╦══════════════╬══════════════╣╠═══════════════╬══════════════╦═══════════╗           ╚══════════════╬══════════════╬══════════════╬══════════════╬══════════════╬══════════════╣
      // ║    &trans    ║    &trans    ║    &trans    ║    &trans    ║    &trans    ║                ║     &trans     ║    &trans    ║   &to BASE   ║║   &to BASE    ║    &trans    ║  &trans   ║                          ║    &trans    ║    &trans    ║  &tog PDES   ║&tog CONSTRAIN║    &trans    ║
      // ╚══════════════╩══════════════╩══════════════╩══════════════╩══════════════╝                ╚════════════════╩══════════════╩══════════════╝╚═══════════════╩══════════════╩═══════════╝                          ╚══════════════╩══════════════╩══════════════╩══════════════╩══════════════╝
            bindings = <
        &kp F1 &kp F2 &kp F3 &kp F4 &kp F5 &kp F6  &none                                                                         &none &kp F7 &kp F8 &kp F9 &kp F10 &kp F11 &kp F12
        &trans &trans &tog WIKI &trans &trans &trans  &none                                                                         &none &trans &trans &trans &trans  &trans  &trans
        &trans &trans &tog SYM &trans &trans &trans  &none                      &trans &trans         &trans &trans                &none &trans &trans &tog KICAD &trans  &trans  &trans
        &trans &trans &trans &tog SKCH &tog VSC &trans                                    &trans         &trans                             &trans &trans &trans &trans  &trans  &trans
        &trans &trans &trans &trans &trans                             &trans &trans &to BASE  &to BASE &trans &trans                             &trans &trans &tog PDES &tog CONSTRAINTS &trans
      >;
    };

    mod {
      display-name = "Mod";
      // ╔══════════════╦══════════════╦══════════════╦══════════════╦══════════════╦══════════════╦══════════════╗                                                                          ╔══════════════╦══════════════╦══════════════╦══════════════╦══════════════╦══════════════╦══════════════╗
      // ║  &bt BT_CLR  ║ &bt BT_SEL 0 ║ &bt BT_SEL 1 ║ &bt BT_SEL 2 ║ &bt BT_SEL 3 ║ &bt BT_SEL 4 ║    &none     ║                                                                          ║    &trans    ║    &none     ║    &none     ║    &none     ║    &none     ║    &none     ║    &none     ║
      // ╠══════════════╬══════════════╬══════════════╬══════════════╬══════════════╬══════════════╬══════════════╣                                                                          ╠══════════════╬══════════════╬══════════════╬══════════════╬══════════════╬══════════════╬══════════════╣
      // ║    &none     ║    &none     ║    &none     ║    &none     ║    &none     ║    &none     ║ &bootloader  ║                                                                          ║ &bootloader  ║    &none     ║    &none     ║    &none     ║    &none     ║    &none     ║    &none     ║
      // ╠══════════════╬══════════════╬══════════════╬══════════════╬══════════════╬══════════════╬══════════════╣   ╔══════════════╦══════════════╗╔═══════════════╦══════════════╗        ╠══════════════╬══════════════╬══════════════╬══════════════╬══════════════╬══════════════╬══════════════╣
      // ║    &none     ║    &none     ║    &none     ║    &none     ║    &none     ║    &none     ║    &none     ║   ║    &none     ║    &none     ║║  &bt BT_CLR   ║ &stp STP_BAT ║        ║    &none     ║    &none     ║    &none     ║    &none     ║    &none     ║    &none     ║    &none     ║
      // ║              ║              ║              ║              ║              ║              ║              ║   ║              ║              ║║               ║              ║        ║              ║              ║              ║              ║              ║              ║              ║
      // ╠══════════════╬══════════════╬══════════════╬══════════════╬══════════════╬══════════════╬══════════════╝   ╚══════════════╬══════════════╣╠═══════════════╬══════════════╝        ╚══════════════╬══════════════╬══════════════╬══════════════╬══════════════╬══════════════╬══════════════╣
      // ║    &none     ║    &none     ║    &none     ║    &none     ║  &macro_ver  ║    &none     ║                                 ║    &none     ║║     &none     ║                                      ║    &none     ║    &none     ║    &none     ║    &none     ║    &none     ║    &none     ║
      // ╠══════════════╬══════════════╬══════════════╬══════════════╬══════════════╬══════════════╝ ╔════════════════╦══════════════╬══════════════╣╠═══════════════╬══════════════╦═══════════╗           ╚══════════════╬══════════════╬══════════════╬══════════════╬══════════════╬══════════════╣
      // ║    &none     ║    &none     ║    &none     ║    &none     ║    &none     ║                ║     &none      ║    &none     ║    &none     ║║     &none     ║  &bl BL_TOG  ║&rgb_ug RGB║                          ║  &bl BL_INC  ║  &bl BL_DEC  ║    &none     ║    &none     ║    &none     ║
      // ╚══════════════╩══════════════╩══════════════╩══════════════╩══════════════╝                ╚════════════════╩══════════════╩══════════════╝╚═══════════════╩══════════════╩═══════════╝                          ╚══════════════╩══════════════╩══════════════╩══════════════╩══════════════╝
            bindings = <
        &bt BT_CLR &bt BT_SEL 0 &bt BT_SEL 1 &bt BT_SEL 2 &bt BT_SEL 3 &bt BT_SEL 4 &none                                                                     &trans                 &none        &none        &none        &none &none &none
        &none      &none        &none        &none        &none        &none        &bootloader                                                               &bootloader            &none        &none        &none        &none &none &none
        &none      &none        &none        &none        &none        &none        &none              &none &none      &bt BT_CLR &stp STP_BAT         &none                  &none        &none        &none        &none &none &none
        &none      &none        &none        &none        &macro_ver   &none                                 &none      &none                                                        &none        &none        &none        &none &none &none
        &none      &none        &none        &none        &none                                  &none &none &none      &none &bl BL_TOG &rgb_ug RGB_TOG                                          &bl BL_INC   &bl BL_DEC   &none &none &none
      >;
    };
  };
};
